# A64 register map
Vendor: Allwinner; Series: A64; File version: 0.1
CPU: CA53 0, little endian, MPU, no FPU, 0 interrupt priority bits
Registers are 32-bit, read-write, reset 0x0 unless marked. A register's access mark holds for its fields unless they carry their own. Offsets are from the block's base; [hi:lo] are bit positions; {n}, {i} and the like mark numbered series; 'fields as' and 'values as' point back to an identical list.

## CCU (part 1 of 2)
Base 0x01C20000
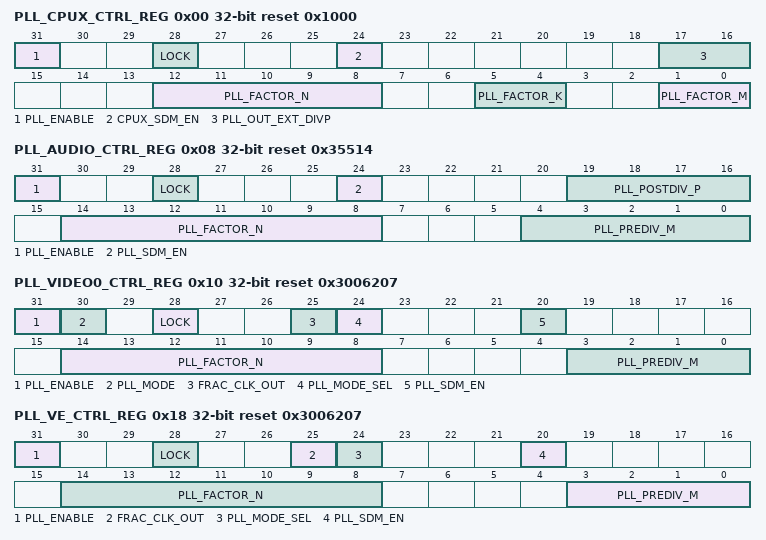
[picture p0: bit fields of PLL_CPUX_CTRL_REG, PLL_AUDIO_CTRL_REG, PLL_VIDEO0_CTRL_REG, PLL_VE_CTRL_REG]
0x00 PLL_CPUX_CTRL_REG reset 0x1000 — PLL_CPUX Control Register
  [31] PLL_ENABLE — 0: Disable 1: Enable The PLL Output= (24MHz*N*K)/(M*P). The PLL output is for the CPUX Clock. Note: 10 N*K 88,The P factor only can be used when PLL output frequency is less than 240MHz. The PLL output clock must be in the range of 240MHz~2.1GHz. The default of CPUX Clock is 408MHz.
    0=Disable; 1=Enable The PLL Output= (24MHz*N*K)/(M*P). The PLL output is for the CPUX Clock. Note: 10 N*K 88,The P factor only can be used when PLL output frequency is less than 240MHz. The PLL output clock must be in the range of 240MHz~2.1GHz. The default of CPUX Clock is 408MHz.
  [28] LOCK ro — 0: Unlocked 1: Locked (It indicates that the PLL has been stable.)
    0=Unlocked; 1=Locked (It indicates that the PLL has been stable.)
  [24] CPUX_SDM_EN — 0: Disable 1: Enable
    0=Disable; 1=Enable
  [17:16] PLL_OUT_EXT_DIVP — PLL Output external divider P 00: /1 01: /2 10: /4 11: /
    0=_slash_1 (/1); 1=_slash_2 (/2); 2=_slash_4 (/4)
  [12:8] PLL_FACTOR_N — PLL Factor N. Factor=0, N=1 Factor=1, N=2 Factor=2, N=3 ... Factor=31, N=32
  [5:4] PLL_FACTOR_K — PLL Factor K.(K=Factor + 1 ) The range is from 1 to 4.
  [1:0] PLL_FACTOR_M — PLL Factor M. (M=Factor + 1) The range is from 1 to 4.
0x08 PLL_AUDIO_CTRL_REG reset 0x35514 — PLL_AUDIO Control Register
  [31] PLL_ENABLE — 0: Disable 1: Enable. The PLL is for Audio. The PLL_AUDIO= (24MHz*N)/(M*P). The PLL_AUDIO(8X) = (24MHz*N*2)/M Note: 3 N/M 21. (24MHz*N)/P must be in the range of 72MHz~504MHz. PLL_AUDIO default is 24.571MHz.
    0=Disable; 1=Enable. The PLL is for Audio. The PLL_AUDIO= (24MHz*N)/(M*P). The PLL_AUDIO(8X) = (24MHz*N*2)/M Note: 3 N/M 21. (24MHz*N)/P must be in the range of 72MHz~504MHz. PLL_AUDIO default is 24.571MHz.
  [28] LOCK ro — 0: Unlocked 1: Locked (It indicates that the PLL has been stable.)
    values as PLL_CPUX_CTRL_REG.LOCK
  [24] PLL_SDM_EN — 0: Disable 1: Enable. In this case, the PLL_FACTOR_N only low 4 bits are valid (N: The range is from 1 to 16).
    0=Disable; 1=Enable. In this case, the PLL_FACTOR_N only low 4 bits are valid (N: The range is from 1 to 16).
  [19:16] PLL_POSTDIV_P — Post-div factor (P= Factor+1) The range is from 1 to 16.
  [14:8] PLL_FACTOR_N — PLL Factor N. Factor=0, N=1 Factor=1, N=2 ... Factor=127, N=128.
  [4:0] PLL_PREDIV_M — PLL Pre-div Factor(M = Factor+1). The range is from 1 to 32.
0x10 PLL_VIDEO0_CTRL_REG reset 0x3006207 — PLL_VIDEO0 Control Register
  [31] PLL_ENABLE — 0: Disable 1: Enable. In the integer mode, PLL_VIDEO0(1X) = (24MHz*N)/M. PLL_VIDEO0(2X) =( (24MHz*N)/M)*2. In the fractional mode, the PLL Output is select by bit 25. Note: 8 N/M 25 (24MHz*N)/M must be in the range of 192MHz~600MHz. PLL_VIDEO0(1X) default is 297MHz.
    0=Disable; 1=Enable. In the integer mode, PLL_VIDEO0(1X) = (24MHz*N)/M. PLL_VIDEO0(2X) =( (24MHz*N)/M)*2. In the fractional mode, the PLL Output is select by bit 25. Note: 8 N/M 25 (24MHz*N)/M must be in the range of 192MHz~600MHz. PLL_VIDEO0(1X) default is 297MHz.
  [30] PLL_MODE — 0: Manual Mode 1: Auto Mode (Controlled by DE).
    0=Manual Mode; 1=Auto Mode (Controlled by DE)
  [28] LOCK ro — 0: Unlocked 1: Locked (It indicates that the PLL has been stable.)
    values as PLL_CPUX_CTRL_REG.LOCK
  [25] FRAC_CLK_OUT — PLL clock output when PLL_MODE_SEL=0(PLL_PREDIV_M factor must be set to 0); No meaning when PLL_MODE_SEL =1. 0: PLL Output=270MHz 1: PLL Output =297MHz.
    0=PLL_Output_equals_270MHz (PLL Output=270MHz); 1=PLL Output =297MHz
  [24] PLL_MODE_SEL — 0: Fractional Mode 1: Integer Mode. Note: When in Fractional mode, the Per Divider M should be set to 0.
    0=Fractional Mode; 1=Integer Mode. Note: When in Fractional mode, the Per Divider M should be set to 0.
  [20] PLL_SDM_EN — 0: Disable 1: Enable.
    0=Disable; 1=Enable
  [14:8] PLL_FACTOR_N — PLL Factor N. Factor=0, N=1 Factor=1, N=2 Factor=2, N=3 ... Factor=127,N=128.
  [3:0] PLL_PREDIV_M — PLL Pre-div Factor(M = Factor+1). The range is from 1 to 16.
0x18 PLL_VE_CTRL_REG reset 0x3006207 — PLL_VE Control Register
  [31] PLL_ENABLE — 0: Disable 1: Enable. In the integer mode, The PLL_VE = (24MHz*N)/M. In the fractional mode, the PLL Output is select by bit 25. Note: 8 N/M 25 (24MHz*N)/M must be in the range of 192MHz~600MHz. PLL_VE default is 297MHz.
    0=Disable; 1=Enable. In the integer mode, The PLL_VE = (24MHz*N)/M. In the fractional mode, the PLL Output is select by bit 25. Note: 8 N/M 25 (24MHz*N)/M must be in the range of 192MHz~600MHz. PLL_VE default is 297MHz.
  [28] LOCK ro — 0: Unlocked 1: Locked (It indicates that the PLL has been stable.)
    values as PLL_CPUX_CTRL_REG.LOCK
  [25] FRAC_CLK_OUT — PLL clock output when PLL_MODE_SEL=0(PLL_PREDIV_M factor must be set to 0); No meaning when PLL_MODE_SEL =1. 0: PLL Output=270MHz 1: PLL Output =297MHz.
    values as PLL_VIDEO0_CTRL_REG.FRAC_CLK_OUT
  [24] PLL_MODE_SEL — 0: Fractional Mode 1: Integer Mode. Note: When in Fractional mode, the Per Divider M should be set to 0.
    values as PLL_VIDEO0_CTRL_REG.PLL_MODE_SEL
  [20] PLL_SDM_EN — 0: Disable 1: Enable. 19:15 / / /
    0=Disable; 1=Enable. 19:15 / / /
  [14:8] PLL_FACTOR_N — PLL Factor N. Factor=0, N=1 Factor=1, N=2 Factor=2, N=3 ... Factor=31,N=32 ... Factor=127,N=128.
  [3:0] PLL_PREDIV_M — PLL Pre Divider (M = Factor+1). The range is from 1 to 16.
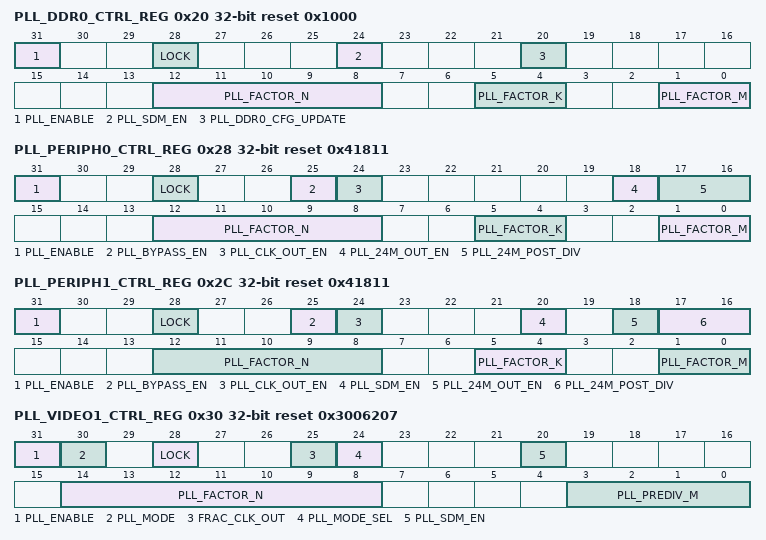
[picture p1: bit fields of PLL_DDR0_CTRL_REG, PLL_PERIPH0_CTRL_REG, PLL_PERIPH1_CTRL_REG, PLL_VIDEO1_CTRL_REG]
0x20 PLL_DDR0_CTRL_REG reset 0x1000 — PLL_DDR0 Control Register
  [31] PLL_ENABLE — 0: Disable 1: Enable. The PLL_DDR0 = (24MHz*N*K)/M. Note: 10 N*K 77(give priority to the choice of K 2) (24MHz*N*K) must be in the range of 240MHz~1.8GHz. PLL_DDR0 default is 408MHz.
    0=Disable; 1=Enable. The PLL_DDR0 = (24MHz*N*K)/M. Note: 10 N*K 77(give priority to the choice of K 2) (24MHz*N*K) must be in the range of 240MHz~1.8GHz. PLL_DDR0 default is 408MHz.
  [28] LOCK ro — 0: Unlocked 1: Locked (It indicates that the PLL has been stable.)
    values as PLL_CPUX_CTRL_REG.LOCK
  [24] PLL_SDM_EN — 0: Disable 1: Enable.
    0=Disable; 1=Enable
  [20] PLL_DDR0_CFG_UPDATE — PLL_DDR0 Configuration Update. When PLL_DDR0 has been changed, this bit should be set to 1 to validate the PLL, otherwise the change would be invalid. And this bit would be cleared automatically after the PLL change is valid. 0: No effect 1: Validating the PLL_DDR0.
    0=No_effect; 1=Validating the PLL_DDR0
  [12:8] PLL_FACTOR_N — PLL Factor N. Factor=0, N=1 Factor=1, N=2 Factor=2, N=3 ... Factor=31,N=32.
  [5:4] PLL_FACTOR_K — PLL Factor K.(K=Factor + 1 ) The range is from 1 to 4.
  [1:0] PLL_FACTOR_M — PLL Factor M.(M = Factor + 1 ) The range is from 1 to 4.
0x28 PLL_PERIPH0_CTRL_REG reset 0x41811 — PLL_PERIPH0 Control Register
  [31] PLL_ENABLE — 0: Disable 1: Enable. The PLL_PERIPH0(1X) = 24MHz*N*K/2. The PLL_PERIPH0(2X) = 24MHz*N*K. Note: 21 N*K 58(give priority to the choice of K 2) The PLL_PERIPH0(2X) should be fixed to 1.2GHz, it is not recommended to vary this value arbitrarily. 24MHz*N*K clock must be in the range of 504MHz~1.4GHz. PLL_PERIPH0(2X) default is 1.2GHz.
    0=Disable; 1=Enable. The PLL_PERIPH0(1X) = 24MHz*N*K/2. The PLL_PERIPH0(2X) = 24MHz*N*K. Note: 21 N*K 58(give priority to the choice of K 2) The PLL_PERIPH0(2X) should be fixed to 1.2GHz, it is not recommended to vary this value arbitrarily. 24MHz*N*K clock must be in the range of 504MHz~1.4GHz. PLL_PERIPH0(2X) default is 1.2GHz.
  [28] LOCK ro — 0: Unlocked 1: Locked (It indicates that the PLL has been stable.)
    values as PLL_CPUX_CTRL_REG.LOCK
  [25] PLL_BYPASS_EN — PLL Output Bypass Enable. 0: Disable 1: Enable If the bypass is enabled, the PLL output is 24MHz.
    0=Disable; 1=Enable If the bypass is enabled, the PLL output is 24MHz
  [24] PLL_CLK_OUT_EN — PLL clock output enable. 0: Disable 1: Enable
    0=Disable; 1=Enable
  [18] PLL_24M_OUT_EN — PLL 24MHz Output Enable. 0: Disable 1: Enable When 25MHz crystal used, this PLL can output 24MHz.
    0=Disable; 1=Enable When 25MHz crystal used, this PLL can output 24MHz
  [17:16] PLL_24M_POST_DIV — PLL 24M Output Clock Post Divider (When 25MHz crystal used). 1/2/3/4.
  [12:8] PLL_FACTOR_N — PLL Factor N. Factor=0, N=1 Factor=1, N=2 Factor=2, N=3 ... Factor=31, N=32
  [5:4] PLL_FACTOR_K — PLL Factor K.(K=Factor + 1 ) The range is from 1 to 4.
  [1:0] PLL_FACTOR_M — PLL Factor M (M = Factor + 1) is only valid in plltest debug. The PLL_PERIPH back door clock output =24MHz*N*K/M. The range is from 1 to 4.
0x2C PLL_PERIPH1_CTRL_REG reset 0x41811 — PLL_PERIPH1 Control Register
  [31] PLL_ENABLE — 0: Disable 1: Enable. The PLL_PERIPH0(1X) = 24MHz*N*K/2. The PLL_PERIPH0(2X) = 24MHz*N*K. Note: 21 N*K 58(give priority to the choice of K 2) The PLL_PERIPH1(2X) should be fixed to 1.2GHz, it is not recommended to vary this value arbitrarily. 24MHz*N*K clock must be in the range of 504MHz~1.4GHz. PLL_PERIPH0(2X) default is 1.2GHz.
    0=Disable; 1=Enable. The PLL_PERIPH0(1X) = 24MHz*N*K/2. The PLL_PERIPH0(2X) = 24MHz*N*K. Note: 21 N*K 58(give priority to the choice of K 2) The PLL_PERIPH1(2X) should be fixed to 1.2GHz, it is not recommended to vary this value arbitrarily. 24MHz*N*K clock must be in the range of 504MHz~1.4GHz. PLL_PERIPH0(2X) default is 1.2GHz.
  [28] LOCK ro — 0: Unlocked 1: Locked (It indicates that the PLL has been stable.)
    values as PLL_CPUX_CTRL_REG.LOCK
  [25] PLL_BYPASS_EN — PLL Output Bypass Enable. 0: Disable 1: Enable. If the bypass is enabled, the PLL output is 24MHz.
    0=Disable; 1=Enable. If the bypass is enabled, the PLL output is 24MHz.
  [24] PLL_CLK_OUT_EN — PLL clock output enable.(Just for the SATA Phy) 0: Disable 1: Enable. 23:21 / / /
    0=Disable; 1=Enable. 23:21 / / /
  [20] PLL_SDM_EN — 0: Disable 1: Enable.
    0=Disable; 1=Enable
  [18] PLL_24M_OUT_EN — PLL 24MHz Output Enable. 0: Disable 1: Enable. When 25MHz crystal used, this PLL can output 24MHz.
    0=Disable; 1=Enable. When 25MHz crystal used, this PLL can output 24MHz.
  [17:16] PLL_24M_POST_DIV — PLL 24M Output Clock Post Divider (When 25MHz crystal used). 1/2/3/4.
  [12:8] PLL_FACTOR_N — PLL Factor N. Factor=0, N=1 Factor=1, N=2 Factor=2, N=3 ... Factor=31,N=32.
  [5:4] PLL_FACTOR_K — PLL Factor K.(K=Factor + 1 ) The range is from 1 to 4.
  [1:0] PLL_FACTOR_M — PLL Factor M (M = Factor + 1) is only valid in plltest debug. The PLL_PERIPH back door clock output =24MHz*N*K/M. The range is from 1 to 4.
0x30 PLL_VIDEO1_CTRL_REG reset 0x3006207 — PLL_VIDEO1 Control Register
  [31] PLL_ENABLE — 0: Disable 1: Enable. In the integer mode, PLL_VIDEO1(1X) = (24MHz*N)/M. PLL_VIDEO1(2X) =( (24MHz*N)/M)*2. In the fractional mode, the PLL Output is select by bit 25. Note: 8 N/M 25 (24MHz*N)/M must be in the range of 192MHz~600MHz. PLL_VIDEO1(1X) default is 297MHz.
    0=Disable; 1=Enable. In the integer mode, PLL_VIDEO1(1X) = (24MHz*N)/M. PLL_VIDEO1(2X) =( (24MHz*N)/M)*2. In the fractional mode, the PLL Output is select by bit 25. Note: 8 N/M 25 (24MHz*N)/M must be in the range of 192MHz~600MHz. PLL_VIDEO1(1X) default is 297MHz.
  [30] PLL_MODE — 0: Manual Mode 1: Auto Mode (Controlled by DE).
    0=Manual Mode; 1=Auto Mode (Controlled by DE)
  [28] LOCK ro — 0: Unlocked 1: Locked (It indicates that the PLL has been stable.)
    values as PLL_CPUX_CTRL_REG.LOCK
  [25] FRAC_CLK_OUT — PLL clock output when PLL_MODE_SEL=0(PLL_PREDIV_M factor must be set to 0); No meaning when PLL_MODE_SEL =1. 0: PLL Output=270MHz 1: PLL Output =297MHz.
    values as PLL_VIDEO0_CTRL_REG.FRAC_CLK_OUT
  [24] PLL_MODE_SEL — 0: Fractional Mode 1: Integer Mode. Note: When in Fractional mode, the Per Divider M should be set to 0.
    values as PLL_VIDEO0_CTRL_REG.PLL_MODE_SEL
  [20] PLL_SDM_EN — 0: Disable 1: Enable.
    0=Disable; 1=Enable
  [14:8] PLL_FACTOR_N — PLL Factor N. Factor=0, N=1 Factor=1, N=2 Factor=2, N=3 ... Factor=127,N=128.
  [3:0] PLL_PREDIV_M — PLL Pre-div Factor(M = Factor+1). The range is from 1 to 16.
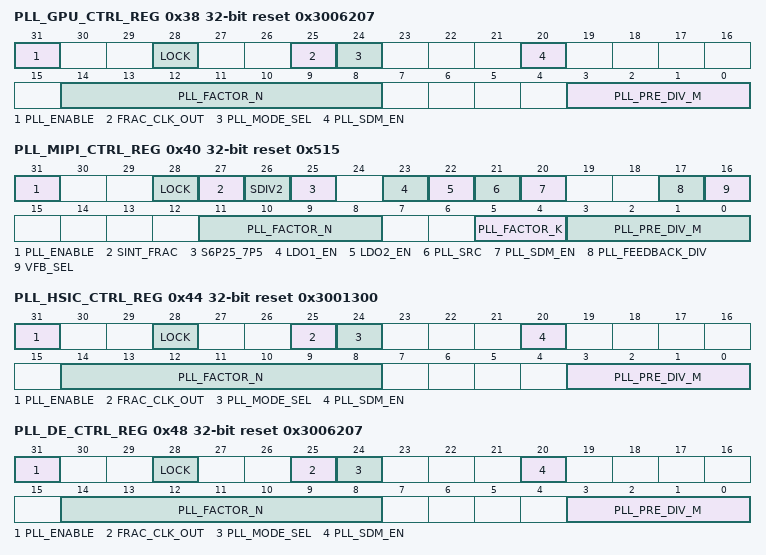
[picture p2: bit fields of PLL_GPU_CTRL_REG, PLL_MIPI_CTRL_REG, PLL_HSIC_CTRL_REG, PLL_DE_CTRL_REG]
0x38 PLL_GPU_CTRL_REG reset 0x3006207 — PLL_GPU Control Register
  [31] PLL_ENABLE — 0: Disable 1: Enable. In the integer mode, The PLL_GPU = (24MHz*N)/M. In the fractional mode, the PLL Output is select by bit 25. Note: 8 N/M 25 (24MHz*N)/M must be in the range of 192MHz~600MHz. PLL_GPU default is 297MHz.
    0=Disable; 1=Enable. In the integer mode, The PLL_GPU = (24MHz*N)/M. In the fractional mode, the PLL Output is select by bit 25. Note: 8 N/M 25 (24MHz*N)/M must be in the range of 192MHz~600MHz. PLL_GPU default is 297MHz.
  [28] LOCK ro — 0: Unlocked 1: Locked (It indicates that the PLL has been stable.)
    values as PLL_CPUX_CTRL_REG.LOCK
  [25] FRAC_CLK_OUT — PLL clock output when PLL_MODE_SEL=0(PLL_PREDIV_M factor must be set to 0); no meaning when PLL_MODE_SEL =1. 0: PLL Output=270MHz 1: PLL Output=297MHz.
    0=PLL_Output_equals_270MHz (PLL Output=270MHz); 1=PLL_Output_equals_297MHz (PLL Output=297MHz.)
  [24] PLL_MODE_SEL — 0: Fractional Mode. 1: Integer Mode. Note: When in Fractional mode, the Per Divider M should be set to 0.
    values as PLL_VIDEO0_CTRL_REG.PLL_MODE_SEL
  [20] PLL_SDM_EN — 0: Disable 1: Enable.
    0=Disable; 1=Enable
  [14:8] PLL_FACTOR_N — PLL Factor N. Factor=0, N=1 Factor=1, N=2 Factor=2, N=3 ... Factor=127,N=128.
  [3:0] PLL_PRE_DIV_M — PLL Pre Divider (M = Factor+1). The range is from 1 to 16.
0x40 PLL_MIPI_CTRL_REG reset 0x515 — PLL_MIPI Control Register
  [31] PLL_ENABLE — 0: Disable 1: Enable. The PLL_MIPI= (PLL_VIDEO0(1X)*N*K)/M when VFB_SEL=0 (MIPI mode). When VFB_SEL=1, the PLL Output is depend on these bits: sint_frac,sdiv2, s6p25_7p5 , pll_feedback_div.6 Note: K 2;M/N 3; (PLL_VIDEO0)/M 24MHz; PLL_MIPI must be in the range of 500MHz~1.4GHz. PLL_MIPI default value is 594MHz.
    0=Disable; 1=Enable. The PLL_MIPI= (PLL_VIDEO0(1X)*N*K)/M when VFB_SEL=0 (MIPI mode). When VFB_SEL=1, the PLL Output is depend on these bits: sint_frac,sdiv2, s6p25_7p5 , pll_feedback_div.6 Note: K 2;M/N 3; (PLL_VIDEO0)/M 24MHz; PLL_MIPI must be in the range of 500MHz~1.4GHz. PLL_MIPI default value is 594MHz.
  [28] LOCK ro — 0: Unlocked 1: Locked (It indicates that the PLL has been stable.)
    values as PLL_CPUX_CTRL_REG.LOCK
  [27] SINT_FRAC — When VFB_SEL=1, PLL mode control, otherwise no meaning. 0: Integer Mode 1: Fractional Mode.
    0=Integer Mode; 1=Fractional Mode
  [26] SDIV2 — PLL clock output when VFB_SEL=1; no meaning when VFB_SEL =0 0: PLL Output 1: PLL Output X2.
  [25] S6P25_7P5 — PLL Output is selected by this bit when VFB_SEL=1 and SINT_FRAC=1, otherwise no meaning. 0: PLL Output=PLL Input*6.25 1: PLL Output= PLL Input *7.5.
    0=PLL_Output_equals_PLL (PLL Output=PLL Input*6.25); 1=PLL_Output_equals_ (PLL Output= PLL Input *7.5.)
  [23] LDO1_EN — On-chip LDO1 Enable.
  [22] LDO2_EN — On-chip LDO2 Enable.
  [21] PLL_SRC — PLL Source Select. 0: VIDEO0 PLL 1: /.
    0=VIDEO0 (VIDEO0 PLL); 1=_slash_
  [20] PLL_SDM_EN — 0: Disable 1: Enable.
    0=Disable; 1=Enable
  [17] PLL_FEEDBACK_DIV — PLL feed-back divider control. PLL clock output when VFB_SEL=1; no meaning when VFB_SEL =0 0:Divided by 5 1:Divided by 7.
  [16] VFB_SEL — 0: MIPI Mode(N, K, M valid) 1:HDMI Mode(sint_frac,sdiv2,s6p25_7p5 , pll_feedback_div valid)
    0=MIPI (MIPI Mode(N, K, M valid) 1:HDMI Mode(sint_frac,sdiv2,s6p25_7p5 , pll_feedback_div valid))
  [11:8] PLL_FACTOR_N — PLL Factor N. Factor=0, N=1 Factor=1, N=2 ... Factor=15,N=16;
  [5:4] PLL_FACTOR_K — PLL Factor K.(K=Factor + 1 ) The range is from 2 to 4.
  [3:0] PLL_PRE_DIV_M — PLL Pre Divider (M = Factor+1). The range is from 1 to 16.
0x44 PLL_HSIC_CTRL_REG reset 0x3001300 — PLL_HSIC Control Register
  [31] PLL_ENABLE — 0: Disable 1: Enable. In the integer mode, The PLL_HSIC = (24MHz*N)/M. In the fractional mode, the PLL Output is select by bit 25. Note: 8 N/M 25 (24MHz*N)/M must be in the range of 192MHz~600MHz. PLL_HSIC default is 480MHz.
    0=Disable; 1=Enable. In the integer mode, The PLL_HSIC = (24MHz*N)/M. In the fractional mode, the PLL Output is select by bit 25. Note: 8 N/M 25 (24MHz*N)/M must be in the range of 192MHz~600MHz. PLL_HSIC default is 480MHz.
  [28] LOCK ro — 0: Unlocked 1: Locked (It indicates that the PLL has been stable.)
    values as PLL_CPUX_CTRL_REG.LOCK
  [25] FRAC_CLK_OUT — PLL clock output when PLL_MODE_SEL=0(PLL_PREDIV_M factor must be set to 0); no meaning when PLL_MODE_SEL =1. 0: PLL Output=270MHz 1: PLL Output=297MHz.
    values as PLL_GPU_CTRL_REG.FRAC_CLK_OUT
  [24] PLL_MODE_SEL — 0: Fractional Mode 1: Integer Mode. Note: When in Fractional mode, the Per Divider M should be set to 0.
    values as PLL_VIDEO0_CTRL_REG.PLL_MODE_SEL
  [20] PLL_SDM_EN — 0: Disable 1: Enable.
    0=Disable; 1=Enable
  [14:8] PLL_FACTOR_N — PLL Factor N. Factor=0, N=1 Factor=1, N=2 Factor=2, N=3 ... Factor=0x7F,N=128.
  [3:0] PLL_PRE_DIV_M — PLL Per Divider (M = Factor+1). The range is from 1 to 16.
0x48 PLL_DE_CTRL_REG reset 0x3006207 — PLL_DE Control Register
  [31] PLL_ENABLE — 0: Disable 1: Enable In the integer mode, The PLL Output= (24MHz*N)/M. In the fractional mode, the PLL Output is select by bit 25. Note: 8 N/M 25 (24MHz*N)/M must be in the range of 192MHz~600MHz. Its default is 297MHz.
    0=Disable; 1=Enable In the integer mode, The PLL Output= (24MHz*N)/M. In the fractional mode, the PLL Output is select by bit 25. Note: 8 N/M 25 (24MHz*N)/M must be in the range of 192MHz~600MHz. Its default is 297MHz.
  [28] LOCK ro — 0: Unlocked 1: Locked (It indicates that the PLL has been stable.)
    values as PLL_CPUX_CTRL_REG.LOCK
  [25] FRAC_CLK_OUT — PLL clock output when PLL_MODE_SEL=0(PLL_PREDIV_M factor must be set to 0); no meaning when PLL_MODE_SEL =1. 0: PLL Output=270MHz 1: PLL Output =297MHz
    values as PLL_VIDEO0_CTRL_REG.FRAC_CLK_OUT
  [24] PLL_MODE_SEL — 0: Fractional Mode 1: Integer Mode Note: When in Fractional mode, the Pre Divider M should be set to 0.
    0=Fractional Mode; 1=Integer Mode Note: When in Fractional mode, the Pre Divider M should be set to 0
  [20] PLL_SDM_EN — 0: Disable 1: Enable
    0=Disable; 1=Enable
  [14:8] PLL_FACTOR_N — PLL Factor N. Factor=0, N=1 Factor=1, N=2 Factor=2, N=3 ... Factor=0x7F, N=128
  [3:0] PLL_PRE_DIV_M — PLL Per Divider (M = Factor+1). The range is from 1 to 16.
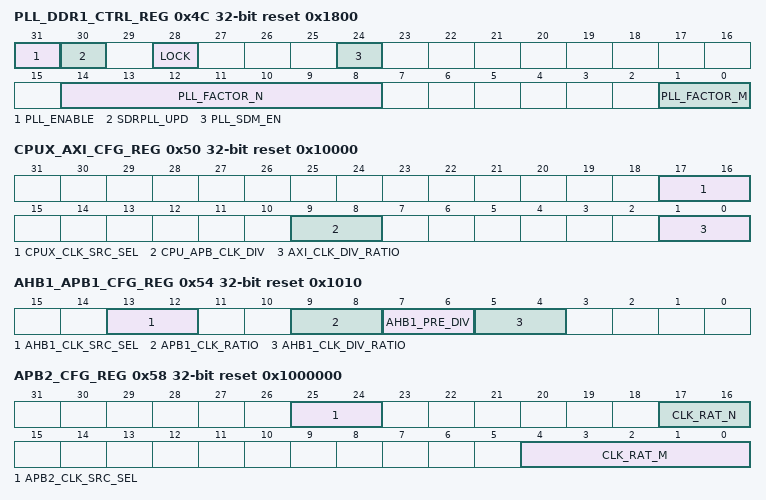
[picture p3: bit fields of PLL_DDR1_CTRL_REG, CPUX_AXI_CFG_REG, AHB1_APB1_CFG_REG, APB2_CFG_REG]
0x4C PLL_DDR1_CTRL_REG reset 0x1800 — PLL_DDR1 Control Register
  [31] PLL_ENABLE — 0: Disable 1: Enable. The PLL_DDR1 = 24MHz*N/M. Note: 16 N 75. 24MHz*N/M must be in the range of 192MHz~1.6GHz. Its default is 600 MHz.
    0=Disable; 1=Enable. The PLL_DDR1 = 24MHz*N/M. Note: 16 N 75. 24MHz*N/M must be in the range of 192MHz~1.6GHz. Its default is 600 MHz.
  [30] SDRPLL_UPD — SDRPLL Configuration Update. Note: When PLL_DDR1 has changed, this bit should be set to 1 to validate the PLL, otherwise the change is invalid. It will be auto cleared after the PLL is valid. 0: No effect 1: To validate the PLL_DDR1.
    0=No_effect; 1=To validate the PLL_DDR1
  [28] LOCK ro — 0:Unlocked 1: Locked (It indicates that the PLL has been stable.)
    1=Locked (It indicates that the PLL has been stable.)
  [24] PLL_SDM_EN — 0: Disable 1: Enable.
    0=Disable; 1=Enable
  [14:8] PLL_FACTOR_N — N= Factor +1. The range is from 0 to 127
  [1:0] PLL_FACTOR_M — M= Factor +1. The range is from 0 to 4
0x50 CPUX_AXI_CFG_REG reset 0x10000
  [17:16] CPUX_CLK_SRC_SEL — CPUX Clock Source Select. CPUX Clock = Clock Source 00: LOSC 01: OSC24M 1X: PLL_CPUX If the clock source is changed, at most to wait for 8 present running clock cycles.
    0=LOSC; 1=OSC24M; 2=PLL_CPUX (PLL_CPUX If the clock source is changed, at most to wait for 8 present running clock cycles.)
  [9:8] CPU_APB_CLK_DIV — 00: /1 01: /2 10: /3 11: /4 Note: System APB clock source is CPU clock source.
    0=_slash_1 (/1); 1=_slash_2 (/2); 2=_slash_3 (/3); 3=_slash_4 (/4 Note: System APB clock source is CPU clock source.)
  [1:0] AXI_CLK_DIV_RATIO — AXI Clock Divide Ratio. AXI Clock source is CPU clock source. 00: /1 01: /2 10: /3 11: /4
    {v}=_slash_{v+1} (/{v+1}) (v=0..3)
0x54 AHB1_APB1_CFG_REG reset 0x1010 — AHB1/APB1 Configuration Register
  [13:12] AHB1_CLK_SRC_SEL — 00: LOSC 01: OSC24M 10: AXI 11: PLL_PERIPH0(1X)/ AHB1_PRE_DIV.
    0=LOSC; 1=OSC24M; 2=AXI; 3=PLL_PERIPH0_openingparen_1X_closingparen__slash_ (PLL_PERIPH0(1X)/ AHB1_PRE_DIV.)
  [9:8] APB1_CLK_RATIO — APB1 Clock Divide Ratio. APB1 clock source is AHB1 clock. 00: /2 01: /2 10: /4 11: /8.
  [7:6] AHB1_PRE_DIV — AHB1 Clock Pre Divide Ratio 00: /1 01: /2 10: /3 11: /4.
    0=_slash_1 (/1); 1=_slash_2 (/2); 2=_slash_3 (/3); 3=_slash_4 (/4.)
  [5:4] AHB1_CLK_DIV_RATIO — AHB1 Clock Divide Ratio. 00: /1 01: /2 10: /4 11: /8.
    0=_slash_1 (/1); 1=_slash_2 (/2); 2=_slash_4 (/4); 3=_slash_8 (/8.)
0x58 APB2_CFG_REG reset 0x1000000
  [25:24] APB2_CLK_SRC_SEL — APB2 Clock Source Select 00: LOSC 01: OSC24M 1X: PLL_PERIPH0(2X). This clock is used for some special module apbclk(UART TWI). Because these modules need special clock rate even if the apb1clk changed.
    0=LOSC; 1=OSC24M; 2=PLL_PERIPH0_openingparen_2X_closingparen_ (PLL_PERIPH0(2X). This clock is used for some special module apbclk(UART TWI). Because these modules need special clock rate even if the apb1clk changed.)
  [17:16] CLK_RAT_N — Clock Per Divide Ratio (n) 00: /1 01: /2 10: /4 11: /8.
    values as AHB1_APB1_CFG_REG.AHB1_CLK_DIV_RATIO
  [4:0] CLK_RAT_M — Clock Divide Ratio (m) The pre-divided clock is divided by (m+1). The divider is from 1 to 32.
0x5C AHB2_CFG_REG — AHB2 Configuration Register
  [1:0] AHB2_CLK_CFG — 00: AHB1 Clock 01: PLL_PERIPH0(1X)/2 1X: / EMAC ,USB HCI0 default clock source is AHB2 Clock. Its default value is 300Mhz.
    0=AHB1 (AHB1 Clock); 1=PLL_PERIPH0_openingparen_1X_closingparen__slash_2 (PLL_PERIPH0(1X)/2); 2=_slash_ (/ EMAC ,USB HCI0 default clock source is AHB2 Clock. Its default value is 300Mhz.)
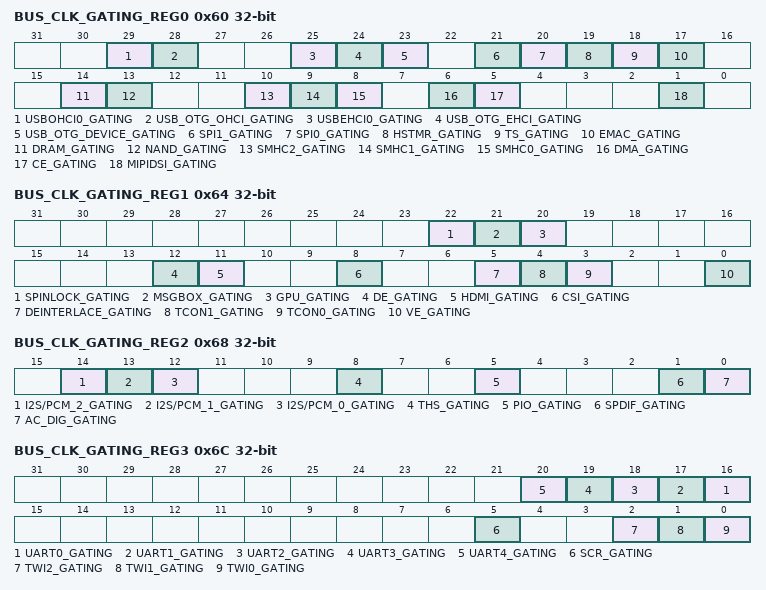
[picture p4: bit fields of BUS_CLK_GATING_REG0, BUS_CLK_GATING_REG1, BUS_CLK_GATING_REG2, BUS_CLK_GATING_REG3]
0x60 BUS_CLK_GATING_REG0 — Bus Clock Gating Register 0
  [all] fields
    0=Mask; 1=Pass
  [29] USBOHCI0_GATING — Gating Clock for USB OHCI0 0: Mask 1: Pass
  [28] USB_OTG_OHCI_GATING — Gating Clock for USB-OTG-OHCI 0: Mask 1: Pass
  [25] USBEHCI0_GATING — Gating Clock For USB EHCI0 0: Mask 1: Pass
  [24] USB_OTG_EHCI_GATING — Gating Clock For USB-OTG-EHCI 0: Mask 1: Pass
  [23] USB_OTG_DEVICE_GATING — USB-OTG-Device_GATING. Gating Clock For USB OTG Device 0: Mask 1: Pass
  [21] SPI1_GATING — Gating Clock For SPI1 0: Mask 1: Pass.
  [20] SPI0_GATING — Gating Clock For SPI0 0: Mask 1: Pass.
  [19] HSTMR_GATING — Gating Clock For High Speed Timer 0: Mask 1: Pass.
  [18] TS_GATING — Gating Clock For TS 0: Mask 1: Pass
  [17] EMAC_GATING — Gating Clock For EMAC 0: Mask 1: Pass
  [14] DRAM_GATING — Gating Clock For DRAM 0: Mask 1: Pass.
  [13] NAND_GATING — Gating Clock For NAND 0: Mask 1: Pass.
  [10] SMHC2_GATING — Gating Clock For SMHC2 0: Mask 1: Pass.
  [9] SMHC1_GATING — Gating Clock For SMHC1 0: Mask 1: Pass.
  [8] SMHC0_GATING — Gating Clock For SMHC0 0: Mask 1: Pass.
  [6] DMA_GATING — Gating Clock For DMA 0: Mask 1: Pass.
  [5] CE_GATING — Gating Clock For CE 0: Mask 1: Pass.
  [1] MIPIDSI_GATING — Gating Clock For MIPI DSI 0: Mask 1: Pass.
0x64 BUS_CLK_GATING_REG1 — Bus Clock Gating Register 1
  [all] fields
    0=Mask; 1=Pass
  [22] SPINLOCK_GATING — 0: Mask 1: Pass.
  [21] MSGBOX_GATING — 0: Mask 1: Pass.
  [20] GPU_GATING — 0: Mask 1: Pass.
  [12] DE_GATING — 0: Mask 1: Pass.
  [11] HDMI_GATING — 0: Mask 1: Pass.
  [8] CSI_GATING — 0: Mask 1: Pass.
  [5] DEINTERLACE_GATING — Gating Clock For DEINTERLACE 0: Mask 1: Pass
  [4] TCON1_GATING — Gating Clock For TCON1 0: Mask 1: Pass.
  [3] TCON0_GATING — Gating Clock For TCON0 0: Mask 1: Pass.
  [0] VE_GATING — Gating Clock For VE 0: Mask 1: Pass.
0x68 BUS_CLK_GATING_REG2 — Bus Clock Gating Register 2
  [all] fields
    0=Mask; 1=Pass
  [14] I2S/PCM_2_GATING — Gating Clock For I2S/PCM-2 0: Mask 1: Pass.
  [13] I2S/PCM_1_GATING — Gating Clock For I2S/PCM-1 0: Mask 1: Pass.
  [12] I2S/PCM_0_GATING — Gating Clock For I2S/PCM-0 0: Mask 1: Pass.
  [8] THS_GATING — Gating Clock For THS 0: Mask 1: Pass
  [5] PIO_GATING — Gating Clock For PIO 0: Mask 1: Pass.
  [1] SPDIF_GATING — Gating Clock For SPDIF 0: Mask 1: Pass
  [0] AC_DIG_GATING — Gating Clock For AC Digital 0: Mask 1: Pass
0x6C BUS_CLK_GATING_REG3 — Bus Clock Gating Register 3
  [all] fields
    0=Mask; 1=Pass
  [n+16] UART{n}_GATING (n=0..4) — Gating Clock For UART{n} 0: Mask 1: Pass.
  [5] SCR_GATING — Gating Clock For SCR 0: Mask 1: Pass
  [2] TWI2_GATING — Gating Clock For TWI2 0: Mask 1: Pass.
  [1] TWI1_GATING — Gating Clock For TWI1 0: Mask 1: Pass.
  [0] TWI0_GATING — Gating Clock For TWI0 0: Mask 1: Pass.
0x70 BUS_CLK_GATING_REG4 — Bus Clock Gating Register 4
  [7] DBGSYS_GATING — Gating Clock For DBGSYS 0: Mask 1: Pass
    0=Mask; 1=Pass
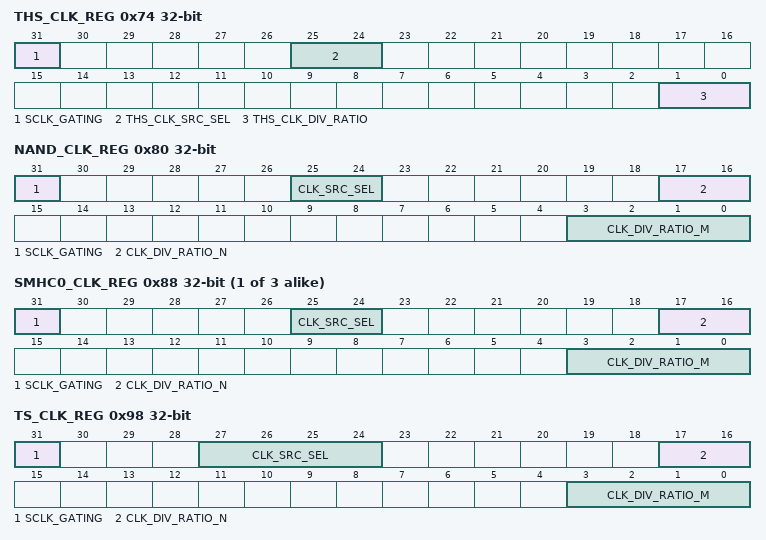
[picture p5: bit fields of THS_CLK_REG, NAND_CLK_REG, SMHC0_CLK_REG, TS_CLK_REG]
0x74 THS_CLK_REG — THS Clock Register
  [31] SCLK_GATING — Gating Special Clock. 0: Clock is OFF 1: Clock is ON This special clock = Clock Source/CLK_DIV_RATIO.
    0=OFF (Clock is OFF); 1=ON (Clock is ON This special clock = Clock Source/CLK_DIV_RATIO.)
  [25:24] THS_CLK_SRC_SEL — Clock Source Select 00: OSC24M 01: / 10: / 11: /
    0=OSC24M
  [1:0] THS_CLK_DIV_RATIO — THS clock divide ratio. 00: /1 01: /2 10: /4 11: /6
    0=_slash_1 (/1); 1=_slash_2 (/2); 2=_slash_4 (/4); 3=_slash_6 (/6)
0x80 NAND_CLK_REG — NAND Clock Register
  [31] SCLK_GATING — Gating Special Clock(Max Clock = 200MHz) 0: Clock is OFF 1: Clock is ON. SCLK = Clock Source/Divider N/Divider M.
    0=OFF (Clock is OFF); 1=ON (Clock is ON. SCLK = Clock Source/Divider N/Divider M.)
  [25:24] CLK_SRC_SEL — Clock Source Select 00: OSC24M 01: PLL_PERIPH0 10: PLL_PERIPH1 11: /
    0=OSC24M; 1=PLL_PERIPH0; 2=PLL_PERIPH1
  [17:16] CLK_DIV_RATIO_N — Clock Pre Divide Ratio (n) 00: /1 01: /2 10: /4 11: /8.
    values as AHB1_APB1_CFG_REG.AHB1_CLK_DIV_RATIO
  [3:0] CLK_DIV_RATIO_M — Clock Divide Ratio (m) The pre-divided clock is divided by (m+1). The divider M is from 1 to 16.
{0x88+4i} SMHC{i}_CLK_REG (i=0..2)
  [31] SCLK_GATING — Gating Special Clock(Max Clock = 384MHz) 0: Clock is OFF 1: Clock is ON. SCLK = Clock Source/Divider N/Divider M.
    values as NAND_CLK_REG.SCLK_GATING
  [25:24] CLK_SRC_SEL — Clock Source Select 00: OSC24M 01: PLL_PERIPH0(2X) 10: PLL_PERIPH1(2X) 11: /.
    0=OSC24M; 1=PLL_PERIPH0_openingparen_2X_closingparen_ (PLL_PERIPH0(2X)); 2=PLL_PERIPH1_openingparen_2X_closingparen_ (PLL_PERIPH1(2X)); 3=_slash_
  [17:16] CLK_DIV_RATIO_N — Clock Pre Divide Ratio (n) 00: /1 01: /2 10: /4 11: /8.
    values as AHB1_APB1_CFG_REG.AHB1_CLK_DIV_RATIO
  [3:0] CLK_DIV_RATIO_M — Clock Divide Ratio (m) The pre-divided clock is divided by (m+1). The divider is from 1 to 16.
0x98 TS_CLK_REG — TS Clock Register
  [31] SCLK_GATING — Gating of SCLK (Max Clock = 200MHz). 0: Clock is OFF 1: Clock is ON SCLK = Clock Source/Divider N/Divider M.
    0=OFF (Clock is OFF); 1=ON (Clock is ON SCLK = Clock Source/Divider N/Divider M.)
  [27:24] CLK_SRC_SEL — Clock Source Select 0000: OSC24M 0001: PLL_PERIPH0(1X) Others: /
    0=OSC24M; 1=PLL_PERIPH0_openingparen_1X_closingparen_ (PLL_PERIPH0(1X) Others: /)
  [17:16] CLK_DIV_RATIO_N — Clock pre-divide ratio (n) The select clock source is pre-divided by 2^n. The divider is 1/2/4/8.
  [3:0] CLK_DIV_RATIO_M — Clock divide ratio (m) The pre-divided clock is divided by (m+1). The divider is from 1 to 16.
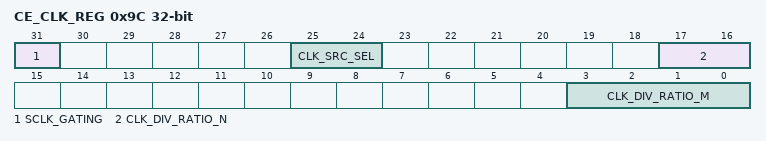
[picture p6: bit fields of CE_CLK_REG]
0x9C CE_CLK_REG — CE Clock Register
  [31] SCLK_GATING — Gating Special Clock(Max Clock = 400MHz) 0: Clock is OFF 1: Clock is ON. SCLK = Clock Source/Divider N/Divider M.
    values as NAND_CLK_REG.SCLK_GATING
  [25:24] CLK_SRC_SEL — Clock Source Select 00: OSC24M 01: PLL_PERIPH0 2X 10: PLL_PERIPH1 2X 11: /.
    0=OSC24M; 1=PLL_PERIPH0 (PLL_PERIPH0 2X); 2=PLL_PERIPH1 (PLL_PERIPH1 2X); 3=_slash_
  [17:16] CLK_DIV_RATIO_N — Clock Pre Divide Ratio (n) 00: /1 01: /2 10: /4 11: /8.
    values as AHB1_APB1_CFG_REG.AHB1_CLK_DIV_RATIO
  [3:0] CLK_DIV_RATIO_M — Clock divide ratio (m) The pre-divided clock is divided by (m+1). The divider is from 1 to 16.
